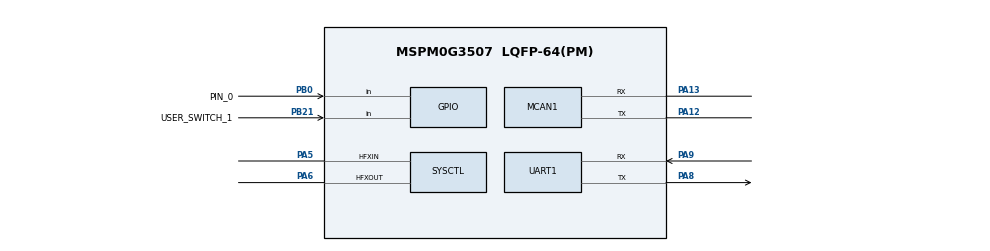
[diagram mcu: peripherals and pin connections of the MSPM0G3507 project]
//@cliArgs --device "MSPM0G350X" --package "LQFP-64(PM)" --part "Default"
//@v2CliArgs --device "MSPM0G3507" --package "LQFP-64(PM)"
// @cliArgs --board /ti/boards/LP_MSPM0G3507 --rtos nortos

/**
 * Import the modules used in this configuration.
 */
const GPIO   = scripting.addModule("/ti/driverlib/GPIO", {}, false);
const GPIO1  = GPIO.addInstance();
const GPIO2  = GPIO.addInstance();
const MCAN   = scripting.addModule("/ti/driverlib/MCAN", {}, false);
const MCAN1  = MCAN.addInstance();
const SYSCTL = scripting.addModule("/ti/driverlib/SYSCTL");
const UART   = scripting.addModule("/ti/driverlib/UART", {}, false);
const UART1  = UART.addInstance();

/**
 * Write custom configuration values to the imported modules.
 */
GPIO1.$name                              = "GPIO_SWITCHES";
GPIO1.port                               = "PORTB";
GPIO1.portSegment                        = "Upper";
GPIO1.associatedPins[0].direction        = "INPUT";
GPIO1.associatedPins[0].internalResistor = "PULL_UP";
GPIO1.associatedPins[0].interruptEn      = true;
GPIO1.associatedPins[0].polarity         = "FALL";
GPIO1.associatedPins[0].$name            = "USER_SWITCH_1";
GPIO1.associatedPins[0].pin.$assign      = "PB21";

const Board = scripting.addModule("/ti/driverlib/Board", {}, false);

GPIO2.$name                         = "GPIO_GRP_0";
GPIO2.port                          = "PORTB";
GPIO2.associatedPins[0].$name       = "PIN_0";
GPIO2.associatedPins[0].direction   = "INPUT";
GPIO2.associatedPins[0].ioStructure = "SD";
GPIO2.associatedPins[0].pin.$assign = "PB0";

MCAN1.$name                    = "MCAN0";
MCAN1.brsEnable                = false;
MCAN1.fdMode                   = false;
MCAN1.wkupReqEnable            = true;
MCAN1.autoWkupEnable           = true;
MCAN1.emulationEnable          = true;
MCAN1.tdcEnable                = true;
MCAN1.stdFiltElem              = "001";
MCAN1.stdFiltType              = "10";
MCAN1.lse                      = 0;
MCAN1.flesa                    = 8;
MCAN1.txStartAddr              = 12;
MCAN1.txFIFOSize               = 4;
MCAN1.txEventFIFOStartAddr     = 452;
MCAN1.txEventFIFOWaterMark     = 0;
MCAN1.rxFIFO0startAddr         = 512;
MCAN1.rxFIFO0size              = 4;
MCAN1.rxFIFO1startAddr         = 804;
MCAN1.rxFIFO1size              = 1;
MCAN1.rxBufStartAddr           = 880;
MCAN1.additionalCoreConfig     = true;
MCAN1.rrfe                     = true;
MCAN1.rrfs                     = true;
MCAN1.anfe                     = "1";
MCAN1.anfs                     = "1";
MCAN1.enableInterrupt          = true;
MCAN1.interruptFlags           = ["DL_MCAN_INTERRUPT_TC"];
MCAN1.interruptLine            = ["DL_MCAN_INTR_LINE_NUM_1"];
MCAN1.interruptLine1Flag       = ["DL_MCAN_INTR_MASK_ALL"];
MCAN1.m0interrupts             = ["DL_MCAN_MSP_INTERRUPT_LINE1"];
MCAN1.peripheral.$assign       = "CANFD0";
MCAN1.peripheral.rxPin.$assign = "PA13";
MCAN1.peripheral.txPin.$assign = "PA12";

SYSCTL.forceDefaultClkConfig        = true;
SYSCTL.useHFCLK_Manual              = true;
SYSCTL.HFCLKSource                  = "HFXT";
SYSCTL.CANCLKSource                 = "HFCLK";
SYSCTL.HFXTStartup                  = 10;
SYSCTL.HFCLK_Freq                   = 40000000;
SYSCTL.HFCLKMonitor                 = true;
SYSCTL.peripheral.$assign           = "SYSCTL";
SYSCTL.peripheral.hfxInPin.$assign  = "PA5";
SYSCTL.peripheral.hfxOutPin.$assign = "PA6";

UART1.$name                    = "UART_0";
UART1.targetBaudRate           = 1000000;
UART1.enableFIFO               = true;
UART1.rxFifoThreshold          = "DL_UART_RX_FIFO_LEVEL_ONE_ENTRY";
UART1.enabledInterrupts        = ["RX"];
UART1.peripheral.$assign       = "UART1";
UART1.peripheral.rxPin.$assign = "PA9";
UART1.peripheral.txPin.$assign = "PA8";
